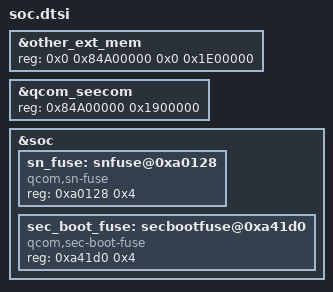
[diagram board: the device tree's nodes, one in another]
&other_ext_mem {
	reg = <0x0 0x84A00000 0x0 0x1E00000>;
};

&qcom_seecom {
	reg = <0x84A00000 0x1900000>;
};

&soc {
	sn_fuse: snfuse@0xa0128 {
		compatible = "qcom,sn-fuse";
		reg = <0xa0128 0x4>;
		reg-names = "sn-base";
	};

	sec_boot_fuse: secbootfuse@0xa41d0 {
		compatible = "qcom,sec-boot-fuse";
		reg = <0xa41d0 0x4>;
		reg-names = "sec-boot-base";
	};
};
